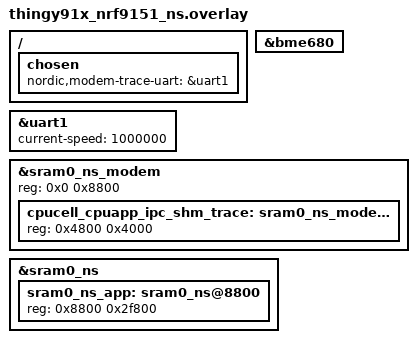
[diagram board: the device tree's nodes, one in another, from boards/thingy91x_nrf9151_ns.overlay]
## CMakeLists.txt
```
cmake_minimum_required(VERSION 3.16)

project(mqtt_questdb_subscriber LANGUAGES CXX)

add_executable(mqtt_questdb_subscriber
    mqtt_questdb_subscriber.cpp
)

target_compile_features(mqtt_questdb_subscriber PRIVATE cxx_std_17)

find_package(PahoMqttCpp REQUIRED)
find_package(PkgConfig REQUIRED)
pkg_check_modules(PQXX REQUIRED IMPORTED_TARGET libpqxx)

target_link_libraries(mqtt_questdb_subscriber PRIVATE
    PahoMqttCpp::paho-mqttpp3
    PkgConfig::PQXX
)
```

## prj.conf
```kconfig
#
# Copyright (c) 2023 Nordic Semiconductor ASA
#
# SPDX-License-Identifier: LicenseRef-Nordic-5-Clause
#

# Common configurations for all boards

# General
CONFIG_HW_ID_LIBRARY=y
CONFIG_ASSERT=y

# Logging
CONFIG_LOG=y

# Networking
CONFIG_NETWORKING=y
CONFIG_NET_SOCKETS_OFFLOAD=y
CONFIG_NET_SOCKETS=y
CONFIG_POSIX_API=y
CONFIG_NET_IPV4=y
CONFIG_NET_TCP=y
CONFIG_NET_NATIVE=y
CONFIG_NET_CONNECTION_MANAGER=y

# ZBus
CONFIG_ZBUS=y

# Zephyr state framework
CONFIG_SMF=y

# MQTT
CONFIG_MQTT_HELPER=y
CONFIG_MQTT_CLEAN_SESSION=y
# Sparkplug NBIRTH includes the full metric schema and current values.
CONFIG_MQTT_HELPER_RX_TX_BUFFER_SIZE=512
CONFIG_DATE_TIME=y
CONFIG_FLASH=y
CONFIG_FLASH_MAP=y
CONFIG_NVS=y
CONFIG_SETTINGS=y
CONFIG_SETTINGS_NVS=y

# Webdock MQTT broker and Thingy:91 X publisher identity/topic.
CONFIG_MQTT_SAMPLE_TRANSPORT_BROKER_HOSTNAME="gruppe7.vps.webdock.cloud"
CONFIG_MQTT_SAMPLE_TRANSPORT_CLIENT_ID="thingy91x-01"
CONFIG_MQTT_SAMPLE_TRANSPORT_PUBLISH_TOPIC="data"
CONFIG_MQTT_SAMPLE_TRIGGER_TIMEOUT_SECONDS=10
CONFIG_MQTT_SAMPLE_TRANSPORT_DUMP_SAMPLE_COUNT=30
CONFIG_MQTT_SAMPLE_TRANSPORT_SAMPLE_BUFFER_SIZE=32

# BME680 sensor readings. The transport serializes numeric samples as Sparkplug B.
CONFIG_SENSOR=y
```

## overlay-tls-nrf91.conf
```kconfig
#
# Copyright (c) 2023 Nordic Semiconductor ASA
#
# SPDX-License-Identifier: LicenseRef-Nordic-5-Clause
#

# Overlay file that enbles TLS for hardware builds

# TLS
CONFIG_MQTT_LIB_TLS=y
CONFIG_MQTT_HELPER_PORT=8883
CONFIG_MQTT_KEEPALIVE=30

# Credentials located under <sample-dir>/src/modules/transport/credentials/ will be automatically
# provisioned to the nRF91 modem prior to connecting to the server.
CONFIG_MODEM_KEY_MGMT=y
CONFIG_MQTT_HELPER_SEC_TAG=955

# Request LTE Power Saving Mode. These requested timers can be overridden by
# the cellular network, and traffic every 10 seconds may prevent deep sleep.
CONFIG_LTE_LC_PSM_MODULE=y
CONFIG_LTE_PSM_REQ=y
CONFIG_LTE_PSM_REQ_FORMAT_SECONDS=y
CONFIG_LTE_PSM_REQ_RPTAU_SECONDS=1800
CONFIG_LTE_PSM_REQ_RAT_SECONDS=10
```

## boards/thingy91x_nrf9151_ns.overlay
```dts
/*
 * Copyright (c) 2024 Nordic Semiconductor ASA
 *
 * SPDX-License-Identifier: LicenseRef-Nordic-5-Clause
 */

/* Enable uart1 for tracing. */
&uart1 {
	status = "okay";
	current-speed = <1000000>;
};

/ {
	chosen {
		nordic,modem-trace-uart = &uart1;
	};
};

/* Enable the onboard BME680 environmental sensor. */
&bme680 {
	status = "okay";
};

/* Increase modem (shared) memory and add trace partition. */
&sram0_ns_modem {
	reg = <0x0 0x8800>;
	ranges = <0x0 0x0 0x8800>;

	cpucell_cpuapp_ipc_shm_trace: sram0_ns_modem@4800 {
		/* Modem trace memory */
		reg = <0x4800 0x4000>;
	};
};

/* Delete Non-Secure application memory so we can move and shrink it. */
/delete-node/ &sram0_ns_app;

&sram0_ns {
	sram0_ns_app: sram0_ns@8800 {
		/* Redefine smaller Non-Secure application memory. */
		reg = <0x8800 0x2f800>;
	};
};
```

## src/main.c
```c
#include <stdio.h>
#include <zephyr/kernel.h>
#include <zephyr/drivers/gpio.h>

#define SLEEP_TIME_MS 250

#define RED_NODE   DT_NODELABEL(red_led)
#define GREEN_NODE DT_NODELABEL(green_led)
#define BLUE_NODE  DT_NODELABEL(blue_led)

static const struct gpio_dt_spec red =
    GPIO_DT_SPEC_GET(RED_NODE, gpios);

static const struct gpio_dt_spec green =
    GPIO_DT_SPEC_GET(GREEN_NODE, gpios);

static const struct gpio_dt_spec blue =
    GPIO_DT_SPEC_GET(BLUE_NODE, gpios);

int main(void)
{
    if (!gpio_is_ready_dt(&red) ||
        !gpio_is_ready_dt(&green) ||
        !gpio_is_ready_dt(&blue)) {
        return 0;
    }

    gpio_pin_configure_dt(&red, GPIO_OUTPUT_INACTIVE);
    gpio_pin_configure_dt(&green, GPIO_OUTPUT_INACTIVE);
    gpio_pin_configure_dt(&blue, GPIO_OUTPUT_INACTIVE);

   while (1) {
    /* RED */
    gpio_pin_set_dt(&red, 1);
    gpio_pin_set_dt(&green, 0);
    gpio_pin_set_dt(&blue, 0);
    k_msleep(SLEEP_TIME_MS);

    /* OFF */
    gpio_pin_set_dt(&red, 0);
    gpio_pin_set_dt(&green, 0);
    gpio_pin_set_dt(&blue, 0);
    k_msleep(SLEEP_TIME_MS);

    /* GREEN */
    gpio_pin_set_dt(&red, 0);
    gpio_pin_set_dt(&green, 1);
    gpio_pin_set_dt(&blue, 0);
    k_msleep(SLEEP_TIME_MS);

    /* OFF */
    gpio_pin_set_dt(&red, 0);
    gpio_pin_set_dt(&green, 0);
    gpio_pin_set_dt(&blue, 0);
    k_msleep(SLEEP_TIME_MS);

    /* BLUE */
    gpio_pin_set_dt(&red, 0);
    gpio_pin_set_dt(&green, 0);
    gpio_pin_set_dt(&blue, 1);
    k_msleep(SLEEP_TIME_MS);

    /* OFF */
    gpio_pin_set_dt(&red, 0);
    gpio_pin_set_dt(&green, 0);
    gpio_pin_set_dt(&blue, 0);
    k_msleep(SLEEP_TIME_MS);

    /* YELLOW */
    gpio_pin_set_dt(&red, 1);
    gpio_pin_set_dt(&green, 1);
    gpio_pin_set_dt(&blue, 0);
    k_msleep(SLEEP_TIME_MS);

    /* OFF */
    gpio_pin_set_dt(&red, 0);
    gpio_pin_set_dt(&green, 0);
    gpio_pin_set_dt(&blue, 0);
    k_msleep(SLEEP_TIME_MS);

    /* MAGENTA */
    gpio_pin_set_dt(&red, 1);
    gpio_pin_set_dt(&green, 0);
    gpio_pin_set_dt(&blue, 1);
    k_msleep(SLEEP_TIME_MS);

    /* OFF */
    gpio_pin_set_dt(&red, 0);
    gpio_pin_set_dt(&green, 0);
    gpio_pin_set_dt(&blue, 0);
    k_msleep(SLEEP_TIME_MS);

    /* CYAN */
    gpio_pin_set_dt(&red, 0);
    gpio_pin_set_dt(&green, 1);
    gpio_pin_set_dt(&blue, 1);
    k_msleep(SLEEP_TIME_MS);

    /* OFF */
    gpio_pin_set_dt(&red, 0);
    gpio_pin_set_dt(&green, 0);
    gpio_pin_set_dt(&blue, 0);
    k_msleep(SLEEP_TIME_MS);

    /* WHITE */
    gpio_pin_set_dt(&red, 1);
    gpio_pin_set_dt(&green, 1);
    gpio_pin_set_dt(&blue, 1);
    k_msleep(SLEEP_TIME_MS);

    /* OFF */
    gpio_pin_set_dt(&red, 0);
    gpio_pin_set_dt(&green, 0);
    gpio_pin_set_dt(&blue, 0);
    k_msleep(SLEEP_TIME_MS);
}

    return 0;
}
```
